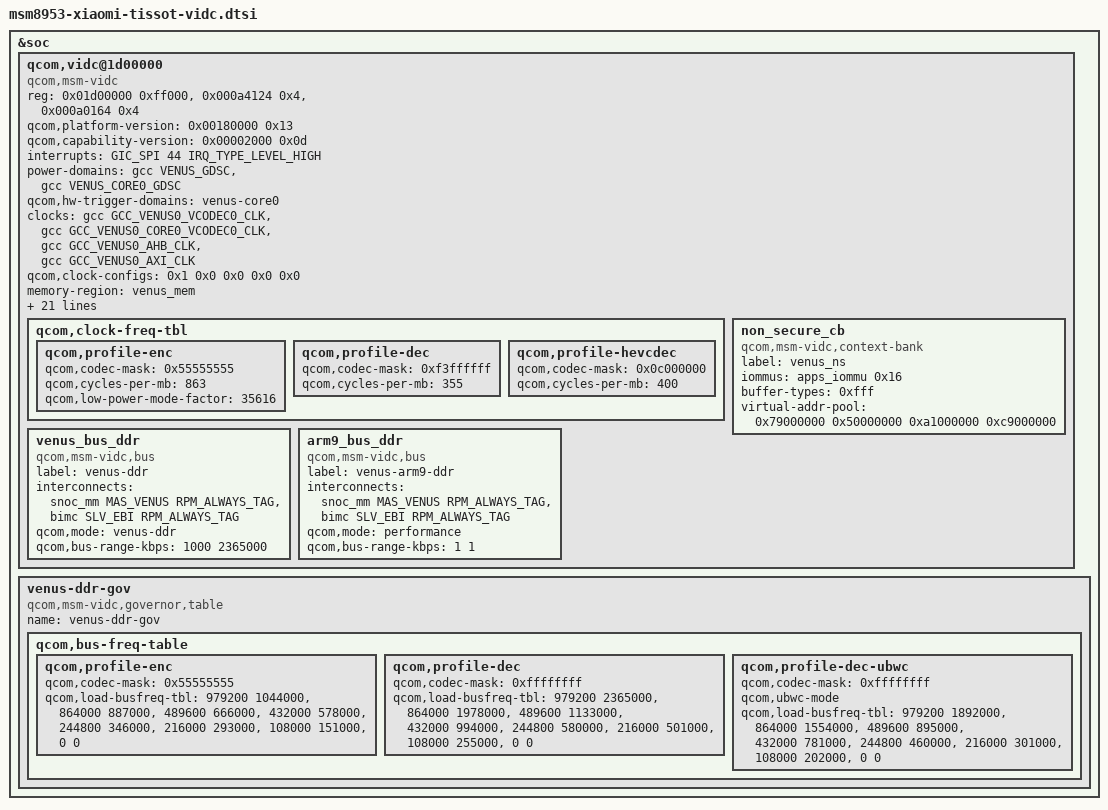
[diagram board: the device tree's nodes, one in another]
// SPDX-License-Identifier: GPL-2.0-only
/*
 * The CAF vidc_3x video codec for tissot (msm8953).
 *
 * The ROM's OMX components (libOmxVdec, libOmxVenc) drive this driver's
 * private V4L2 interface on /dev/video32 and /dev/video33; the upstream
 * Venus driver (msm8953-xiaomi-tissot-venus.dtsi) speaks the standard
 * stateful API, which the ROM has no component for. Both drive the same
 * core and boot the same firmware into the same memory, so only one of
 * the two files may be included, and only one of VIDEO_QCOM_VENUS and
 * MSM_VIDC_3X_V4L2 may be built.
 *
 * This is the donor's msm8953-vidc.dtsi (../oc-test, 4.19 CAF) with the
 * resources translated to this kernel:
 *
 *   - the GDSCs are power domains, not the venus-supply and
 *     venus-core0-supply regulators. The donor's core0 GDSC had
 *     "qcom,support-hw-trigger", which qcom,hw-trigger-domains carries.
 *   - the clocks are the port's GCC ones, under the donor's names.
 *   - the buses vote through the interconnect framework: each bus node
 *     has the path of the donor's MSM_BUS_MASTER_VIDEO_P0 ->
 *     MSM_BUS_SLAVE_EBI_CH0 pair. The donor registered the clients as
 *     not active-only, so the votes are tagged "always".
 *   - the firmware region is named, for the PAS load that the subsystem
 *     compatibility shim does (drivers/soc/qcom/subsystem-compat.c).
 *   - only the non-secure context bank, on the Venus SMMU stream the
 *     upstream driver uses (0x16). The three secure banks need the
 *     TrustZone secure SMMU, which this tree does not have; secure
 *     playback is out of scope. TrustZone's memory protection call
 *     still needs the secure non-pixel bank's range, so it is given
 *     as qcom,cp-nonpixel-range.
 */

#include <dt-bindings/clock/qcom,gcc-msm8953.h>
#include <dt-bindings/interconnect/qcom,msm8953.h>
#include <dt-bindings/interconnect/qcom,rpm-icc.h>
#include <dt-bindings/interrupt-controller/arm-gic.h>

&soc {
	qcom,vidc@1d00000 {
		compatible = "qcom,msm-vidc";
		reg = <0x01d00000 0xff000>,
		      <0x000a4124 0x4>,
		      <0x000a0164 0x4>;
		reg-names = "vidc", "efuse", "efuse2";
		qcom,platform-version = <0x00180000 0x13>;
		qcom,capability-version = <0x00002000 0x0d>;
		interrupts = <GIC_SPI 44 IRQ_TYPE_LEVEL_HIGH>;

		power-domains = <&gcc VENUS_GDSC>, <&gcc VENUS_CORE0_GDSC>;
		power-domain-names = "venus", "venus-core0";
		qcom,hw-trigger-domains = "venus-core0";

		clocks = <&gcc GCC_VENUS0_VCODEC0_CLK>,
			 <&gcc GCC_VENUS0_CORE0_VCODEC0_CLK>,
			 <&gcc GCC_VENUS0_AHB_CLK>,
			 <&gcc GCC_VENUS0_AXI_CLK>;
		clock-names = "core_clk", "core0_clk", "iface_clk", "bus_clk";
		qcom,clock-configs = <0x1 0x0 0x0 0x0 0x0>;

		memory-region = <&venus_mem>;

		qcom,hfi = "venus";
		qcom,hfi-version = "3xx";
		qcom,reg-presets = <0xe0020 0x05555556>,
				   <0xe0024 0x05555556>,
				   <0x80124 0x00000003>;
		qcom,qdss-presets = <0x825000 0x1000>,
				    <0x826000 0x1000>,
				    <0x821000 0x1000>,
				    <0x802000 0x1000>,
				    <0x9180000 0x1000>,
				    <0x9181000 0x1000>;
		qcom,max-hw-load = <1044480>; /* 4096 x 2176 @ 30 fps */
		qcom,slave-side-cp;
		/* The donor's venus_sec_non_pixel virtual-addr-pool. */
		qcom,cp-nonpixel-range = <0x01000000 0x28000000>;
		qcom,sw-power-collapse;
		qcom,firmware-name = "venus";
		qcom,pm-qos-latency-us = <213>;
		qcom,dcvs-tbl =
			/* Dec UHD@30 H.264, HEVC, VP8, VP9 - NOM to NOM+ */
			<816000 816000 979200 0x3f00000c>,
			/* Enc 3840x1920@30 H.264/HEVC Turbo to Nom+ */
			<855000 821100 979200 0x4000004>,
			/* Enc True4K@24 H.264/HEVC Nom to Nom+ */
			<816000 720000 835584 0x4000004>;
		qcom,dcvs-limit =
			<28800 24>, /* Encoder 3840x1920 */
			<32400 24>; /* Decoder UHD */
		qcom,allowed-clock-rates = <465000000 400000000
			360000000 310000000 228570000 114290000>;

		qcom,clock-freq-tbl {
			qcom,profile-enc {
				qcom,codec-mask = <0x55555555>;
				qcom,cycles-per-mb = <863>;
				qcom,low-power-mode-factor = <35616>;
			};

			qcom,profile-dec {
				qcom,codec-mask = <0xf3ffffff>;
				qcom,cycles-per-mb = <355>;
			};

			qcom,profile-hevcdec {
				qcom,codec-mask = <0x0c000000>;
				qcom,cycles-per-mb = <400>;
			};
		};

		non_secure_cb {
			compatible = "qcom,msm-vidc,context-bank";
			label = "venus_ns";
			iommus = <&apps_iommu 0x16>;
			buffer-types = <0xfff>;
			virtual-addr-pool = <0x79000000 0x50000000
					     0xa1000000 0xc9000000>;
		};

		venus_bus_ddr {
			compatible = "qcom,msm-vidc,bus";
			label = "venus-ddr";
			interconnects = <&snoc_mm MAS_VENUS RPM_ALWAYS_TAG
					 &bimc SLV_EBI RPM_ALWAYS_TAG>;
			qcom,mode = "venus-ddr";
			qcom,bus-range-kbps = <1000 2365000>;
		};

		arm9_bus_ddr {
			compatible = "qcom,msm-vidc,bus";
			label = "venus-arm9-ddr";
			interconnects = <&snoc_mm MAS_VENUS RPM_ALWAYS_TAG
					 &bimc SLV_EBI RPM_ALWAYS_TAG>;
			qcom,mode = "performance";
			qcom,bus-range-kbps = <1 1>;
		};
	};

	venus-ddr-gov {
		compatible = "qcom,msm-vidc,governor,table";
		name = "venus-ddr-gov";

		qcom,bus-freq-table {
			qcom,profile-enc {
				qcom,codec-mask = <0x55555555>;
				qcom,load-busfreq-tbl =
					<979200 1044000>,  /* UHD30E     */
					<864000 887000>,   /* 720p240LPE */
					<489600 666000>,   /* 1080p60E   */
					<432000 578000>,   /* 720p120E   */
					<244800 346000>,   /* 1080p30E   */
					<216000 293000>,   /* 720p60E    */
					<108000 151000>,   /* 720p30E    */
					<0 0>;
			};

			qcom,profile-dec {
				qcom,codec-mask = <0xffffffff>;
				qcom,load-busfreq-tbl =
					<979200 2365000>,  /* UHD30D     */
					<864000 1978000>,  /* 720p240D   */
					<489600 1133000>,  /* 1080p60D   */
					<432000 994000>,   /* 720p120D   */
					<244800 580000>,   /* 1080p30D   */
					<216000 501000>,   /* 720p60E    */
					<108000 255000>,   /* 720p30D    */
					<0 0>;
			};

			qcom,profile-dec-ubwc {
				qcom,codec-mask = <0xffffffff>;
				qcom,ubwc-mode;
				qcom,load-busfreq-tbl =
					<979200 1892000>,  /* UHD30D     */
					<864000 1554000>,  /* 720p240D   */
					<489600 895000>,   /* 1080p60D   */
					<432000 781000>,   /* 720p120D   */
					<244800 460000>,   /* 1080p30D   */
					<216000 301000>,   /* 720p60E    */
					<108000 202000>,   /* 720p30D    */
					<0 0>;
			};
		};
	};
};
